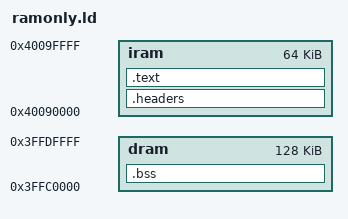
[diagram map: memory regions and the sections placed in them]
/*
 * Copyright (c) 2016 Cesanta Software Limited
 * All rights reserved
 *
 * This program is free software; you can redistribute it and/or modify it under
 * the terms of the GNU General Public License as published by the Free Software
 * Foundation; either version 2 of the License, or (at your option) any later version.
 *
 * This program is distributed in the hope that it will be useful, but WITHOUT
 * ANY WARRANTY; without even the implied warranty of MERCHANTABILITY or FITNESS
 * FOR A PARTICULAR PURPOSE. See the GNU General Public License for more details.
 *
 * You should have received a copy of the GNU General Public License along with
 * this program; if not, write to the Free Software Foundation, Inc., 51 Franklin
 * Street, Fifth Floor, Boston, MA 02110-1301 USA.
 */

MEMORY {
  iram : org = 0x40090000, len = 0x10000
  dram : org = 0x3FFC0000, len = 0x20000
}


SECTIONS {
  .headers : ALIGN(4) {
    KEEP(*(.headers))
  } > iram

  .text : ALIGN(4) {
    *(.literal)
    *(.text .text.*)
  } > iram

  .bss : ALIGN(4) {
     _bss_start = ABSOLUTE(.);
    *(.bss)
	_bss_end = ABSOLUTE(.);
  } > dram
}

ENTRY(FLASHHelperEntry);
INCLUDE F:\SysGCC\esp32\esp32-bsp\sysprogs\esp32.rom.ld

